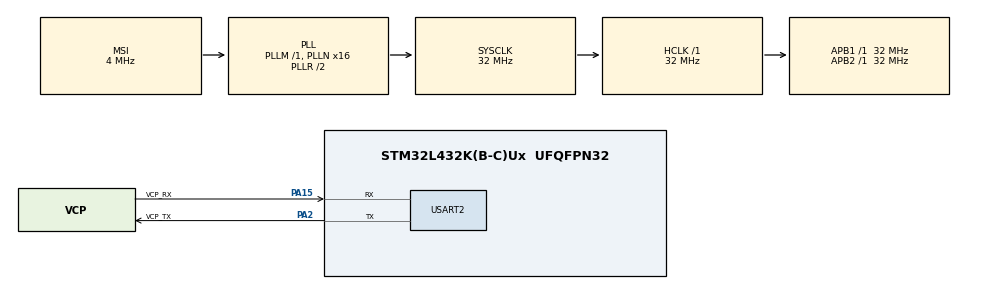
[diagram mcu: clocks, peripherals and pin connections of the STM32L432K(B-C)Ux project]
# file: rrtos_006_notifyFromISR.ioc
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FREERTOS.Tasks01=defaultTask,24,128,StartDefaultTask,Default,NULL,Dynamic,NULL,NULL
FREERTOS.configTOTAL_HEAP_SIZE=4098
FREERTOS.configUSE_NEWLIB_REENTRANT=1
Mcu.Family=STM32L4
Mcu.Name=STM32L432K(B-C)Ux
Mcu.Package=UFQFPN32
NVIC.PriorityGroup=NVIC_PRIORITYGROUP_4
NVIC.TIM1_UP_TIM16_IRQn=true\:6\:0\:true\:false\:true\:true\:true\:true\:true
NVIC.TIM6_DAC_IRQn=true\:15\:0\:false\:false\:true\:false\:false\:true\:true
NVIC.TimeBase=TIM6_DAC_IRQn
NVIC.TimeBaseIP=TIM6
PA0.GPIO_Label=MCO [High speed clock in]
PA0.Mode=HSE-External-Clock-Source-for-LittleOrca
PA0.Signal=RCC_CK_IN
PA13\ (JTMS-SWDIO).GPIO_Label=SWDIO
PA13\ (JTMS-SWDIO).Mode=Serial_Wire
PA13\ (JTMS-SWDIO).Signal=SYS_JTMS-SWDIO
PA14\ (JTCK-SWCLK).GPIO_Label=SWCLK
PA14\ (JTCK-SWCLK).Mode=Serial_Wire
PA14\ (JTCK-SWCLK).Signal=SYS_JTCK-SWCLK
PA15\ (JTDI).GPIO_Label=VCP_RX
PA15\ (JTDI).Mode=Asynchronous
PA15\ (JTDI).Signal=USART2_RX
PA2.GPIO_Label=VCP_TX
PA2.Mode=Asynchronous
PA2.Signal=USART2_TX
PC14-OSC32_IN\ (PC14).Mode=LSE-External-Oscillator
PC14-OSC32_IN\ (PC14).Signal=RCC_OSC32_IN
PC15-OSC32_OUT\ (PC15).Mode=LSE-External-Oscillator
PC15-OSC32_OUT\ (PC15).Signal=RCC_OSC32_OUT
ProjectManager.HeapSize=0x200
ProjectManager.StackSize=0x400
ProjectManager.TargetToolchain=STM32CubeIDE
RCC.AHBFreq_Value=32000000
RCC.APB1Freq_Value=32000000
RCC.APB1TimFreq_Value=32000000
RCC.APB2Freq_Value=32000000
RCC.APB2TimFreq_Value=32000000
RCC.CortexFreq_Value=32000000
RCC.HCLKFreq_Value=32000000
RCC.HSE_VALUE=8000000
RCC.HSI16_VALUE=16000000
RCC.HSI48_VALUE=48000000
RCC.HSI_VALUE=16000000
RCC.MSI_VALUE=4000000
RCC.PLLMUL=RCC_PLLMUL_4
RCC.PLLN=16
RCC.SYSCLKFreq_VALUE=32000000
RCC.SYSCLKSource=RCC_SYSCLKSOURCE_PLLCLK
RCC.VCOOutputFreq_Value=64000000
TIM1.Period=1000-1
TIM1.Prescaler=32000-1
USART2.VirtualMode-Asynchronous=VM_ASYNC
VP_FREERTOS_VS_CMSIS_V2.Mode=CMSIS_V2
VP_SYS_VS_tim6.Mode=TIM6
VP_TIM1_VS_ClockSourceINT.Mode=Internal
board=NUCLEO-L432KC

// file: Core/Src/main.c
/* USER CODE BEGIN Header */
/**
  ******************************************************************************
  * @file           : main.c
  * @brief          : Main program body
  ******************************************************************************
  * @attention
  *
  * Copyright (c) 2025 STMicroelectronics.
  * All rights reserved.
  *
  * This software is licensed under terms that can be found in the LICENSE file
  * in the root directory of this software component.
  * If no LICENSE file comes with this software, it is provided AS-IS.
  *
  ******************************************************************************
  */
/* USER CODE END Header */
#include "main.h"
#include "cmsis_os.h"

/* USER CODE BEGIN Includes */
//NOTE : configLIBRARY_MAX_SYSCALL_INTERRUPT_PRIORITY is 5 , so  for using FromISR() functions , the ISR priority val should be >5
#include"stdint.h"
/* USER CODE END Includes */

TIM_HandleTypeDef htim1;

UART_HandleTypeDef huart2;

/* Definitions for defaultTask */
osThreadId_t defaultTaskHandle;
const osThreadAttr_t defaultTask_attributes = {
  .name = "defaultTask",
  .stack_size = 128 * 4,
  .priority = (osPriority_t) osPriorityNormal,
};
/* USER CODE BEGIN PV */
TaskHandle_t red_handle = NULL;
TaskHandle_t green_handle = NULL;
TaskHandle_t yellow_handle = NULL;
TaskHandle_t button_handle = NULL;
volatile TaskHandle_t* pcurrentHandle = &red_handle;  // initializing with the first task

/*
 *xTaskNotifyFromISR(...)

This sends a notification to a task (pointed to by pcurrentHandle).

It's the ISR-safe version of xTaskNotify().

The last argument &pxHigherPriorityTaskWoken is a pointer to a flag that FreeRTOS sets to pdTRUE if the notified task has higher priority than the task currently running.

portYIELD_FROM_ISR(pxHigherPriorityTaskWoken)

If the notified task is higher priority, this macro tells the scheduler to switch context immediately after the ISR finishes, so that high-priority task can start running right away.

If pxHigherPriorityTaskWoken is pdFALSE, no context switch happens.

🧠 Why this is needed:
In an ISR, FreeRTOS doesn’t switch tasks automatically.

So, if you unblock a higher priority task, and want it to run immediately, you must explicitly request a context switch using portYIELD_FROM_ISR().
 */
 void timerInterruptHandler(void)
 {
	 BaseType_t pxHigherPriorityTaskWoken=pdFAIL;

	 xTaskNotifyFromISR(*(pcurrentHandle),0,eNoAction,&pxHigherPriorityTaskWoken);
	 portYIELD_FROM_ISR(pxHigherPriorityTaskWoken);// requesting context switching manually

 }
/* USER CODE END PV */

void SystemClock_Config(void);
static void MX_GPIO_Init(void);
static void MX_USART2_UART_Init(void);
static void MX_TIM1_Init(void);
void StartDefaultTask(void *argument);

/* USER CODE BEGIN 0 */

/* USER CODE END PFP */

/* Private user code ---------------------------------------------------------*/
/* USER CODE BEGIN 0 */
void red_task(void*);

void green_task(void*);

void yellow_task(void*);
/* USER CODE END 0 */

int main(void)
{

  /* MCU Configuration--------------------------------------------------------*/

  /* Reset of all peripherals, Initializes the Flash interface and the Systick. */
  HAL_Init();

  /* Configure the system clock */
  SystemClock_Config();

  /* Initialize all configured peripherals */
  MX_GPIO_Init();
  MX_USART2_UART_Init();
  MX_TIM1_Init();
  /* USER CODE BEGIN 2 */
  BaseType_t status = 0;

  /* USER CODE END 2 */

  /* Init scheduler */
  osKernelInitialize();

  /* Create the thread(s) */
  /* creation of defaultTask */
  defaultTaskHandle = osThreadNew(StartDefaultTask, NULL, &defaultTask_attributes);

  /* USER CODE BEGIN RTOS_THREADS */
  /* add threads, ... */
  HAL_UART_Transmit(&huart2, (uint8_t*)"Hello\r\n", sizeof("Hello\r\n") - 1, 1000);

//  printHeapSize();
  status = xTaskCreate(red_task, "Led1", 100, NULL, 1, &red_handle);
  if (status != pdPASS) HAL_UART_Transmit(&huart2, (uint8_t*)"Task1 creation failed\r\n", sizeof("Task1 creation failed\r\n") - 1, 1000);
  configASSERT(status == pdPASS);

//  printHeapSize();

  status = xTaskCreate(green_task, "Led2", 100, NULL, 3, &green_handle);
  if (status != pdPASS) HAL_UART_Transmit(&huart2, (uint8_t*)"Task2 creation failed\r\n", sizeof("Task2 creation failed\r\n") - 1, 1000);
  configASSERT(status == pdPASS);

//  printHeapSize();

  status = xTaskCreate(yellow_task, "Led3", 100, NULL, 2, &yellow_handle);
  if (status != pdPASS) HAL_UART_Transmit(&huart2, (uint8_t*)"Task3 creation failed\r\n", sizeof("Task3 creation failed\r\n") - 1, 1000);
  configASSERT(status == pdPASS);
  HAL_UART_Transmit(&huart2, (uint8_t*)"All task created successfully\r\n", sizeof("All task created successfully\r\n") - 1, 1000);

  HAL_TIM_Base_Start_IT(&htim1);
   vTaskStartScheduler();
   HAL_UART_Transmit(&huart2, (uint8_t*)"Scheduler initialization failed\r\n", sizeof("Scheduler initialization failed\r\n") - 1, 1000);

  /* USER CODE END RTOS_THREADS */

  /* Start scheduler */
  osKernelStart();
  /* We should never get here as control is now taken by the scheduler */
  /* Infinite loop */
  while (1)
  {

  }
}

void SystemClock_Config(void)
{
  RCC_OscInitTypeDef RCC_OscInitStruct = {0};
  RCC_ClkInitTypeDef RCC_ClkInitStruct = {0};

  /** Configure the main internal regulator output voltage
  */
  if (HAL_PWREx_ControlVoltageScaling(PWR_REGULATOR_VOLTAGE_SCALE1) != HAL_OK)
  {
    Error_Handler();
  }

  /** Configure LSE Drive Capability
  */
  HAL_PWR_EnableBkUpAccess();
  __HAL_RCC_LSEDRIVE_CONFIG(RCC_LSEDRIVE_LOW);

  /** Initializes the RCC Oscillators according to the specified parameters
  * in the RCC_OscInitTypeDef structure.
  */
  RCC_OscInitStruct.OscillatorType = RCC_OSCILLATORTYPE_LSE|RCC_OSCILLATORTYPE_MSI;
  RCC_OscInitStruct.LSEState = RCC_LSE_ON;
  RCC_OscInitStruct.MSIState = RCC_MSI_ON;
  RCC_OscInitStruct.MSICalibrationValue = 0;
  RCC_OscInitStruct.MSIClockRange = RCC_MSIRANGE_6;
  RCC_OscInitStruct.PLL.PLLState = RCC_PLL_ON;
  RCC_OscInitStruct.PLL.PLLSource = RCC_PLLSOURCE_MSI;
  RCC_OscInitStruct.PLL.PLLM = 1;
  RCC_OscInitStruct.PLL.PLLN = 16;
  RCC_OscInitStruct.PLL.PLLP = RCC_PLLP_DIV7;
  RCC_OscInitStruct.PLL.PLLQ = RCC_PLLQ_DIV2;
  RCC_OscInitStruct.PLL.PLLR = RCC_PLLR_DIV2;
  if (HAL_RCC_OscConfig(&RCC_OscInitStruct) != HAL_OK)
  {
    Error_Handler();
  }

  /** Initializes the CPU, AHB and APB buses clocks
  */
  RCC_ClkInitStruct.ClockType = RCC_CLOCKTYPE_HCLK|RCC_CLOCKTYPE_SYSCLK
                              |RCC_CLOCKTYPE_PCLK1|RCC_CLOCKTYPE_PCLK2;
  RCC_ClkInitStruct.SYSCLKSource = RCC_SYSCLKSOURCE_PLLCLK;
  RCC_ClkInitStruct.AHBCLKDivider = RCC_SYSCLK_DIV1;
  RCC_ClkInitStruct.APB1CLKDivider = RCC_HCLK_DIV1;
  RCC_ClkInitStruct.APB2CLKDivider = RCC_HCLK_DIV1;

  if (HAL_RCC_ClockConfig(&RCC_ClkInitStruct, FLASH_LATENCY_1) != HAL_OK)
  {
    Error_Handler();
  }

  /** Enable MSI Auto calibration
  */
  HAL_RCCEx_EnableMSIPLLMode();
}

static void MX_TIM1_Init(void)
{

  TIM_ClockConfigTypeDef sClockSourceConfig = {0};
  TIM_MasterConfigTypeDef sMasterConfig = {0};

  htim1.Instance = TIM1;
  htim1.Init.Prescaler = 32000-1;
  htim1.Init.CounterMode = TIM_COUNTERMODE_UP;
  htim1.Init.Period = 1000-1;
  htim1.Init.ClockDivision = TIM_CLOCKDIVISION_DIV1;
  htim1.Init.RepetitionCounter = 0;
  htim1.Init.AutoReloadPreload = TIM_AUTORELOAD_PRELOAD_DISABLE;
  if (HAL_TIM_Base_Init(&htim1) != HAL_OK)
  {
    Error_Handler();
  }
  sClockSourceConfig.ClockSource = TIM_CLOCKSOURCE_INTERNAL;
  if (HAL_TIM_ConfigClockSource(&htim1, &sClockSourceConfig) != HAL_OK)
  {
    Error_Handler();
  }
  sMasterConfig.MasterOutputTrigger = TIM_TRGO_RESET;
  sMasterConfig.MasterOutputTrigger2 = TIM_TRGO2_RESET;
  sMasterConfig.MasterSlaveMode = TIM_MASTERSLAVEMODE_DISABLE;
  if (HAL_TIMEx_MasterConfigSynchronization(&htim1, &sMasterConfig) != HAL_OK)
  {
    Error_Handler();
  }

}

static void MX_USART2_UART_Init(void)
{

  huart2.Instance = USART2;
  huart2.Init.BaudRate = 115200;
  huart2.Init.WordLength = UART_WORDLENGTH_8B;
  huart2.Init.StopBits = UART_STOPBITS_1;
  huart2.Init.Parity = UART_PARITY_NONE;
  huart2.Init.Mode = UART_MODE_TX_RX;
  huart2.Init.HwFlowCtl = UART_HWCONTROL_NONE;
  huart2.Init.OverSampling = UART_OVERSAMPLING_16;
  huart2.Init.OneBitSampling = UART_ONE_BIT_SAMPLE_DISABLE;
  huart2.AdvancedInit.AdvFeatureInit = UART_ADVFEATURE_NO_INIT;
  if (HAL_UART_Init(&huart2) != HAL_OK)
  {
    Error_Handler();
  }

}

static void MX_GPIO_Init(void)
{

  /* GPIO Ports Clock Enable */
  __HAL_RCC_GPIOC_CLK_ENABLE();
  __HAL_RCC_GPIOA_CLK_ENABLE();

}

/* USER CODE BEGIN 4 */
void red_task(void* para) {
  while (1) {

    if (xTaskNotifyWait(0, 0, NULL, pdMS_TO_TICKS(1000)) == pdPASS) {
      portENTER_CRITICAL();
      HAL_UART_Transmit(&huart2, (uint8_t*)"Red task Running \r\n", sizeof("Red task Running \r\n") - 1, 1000);
      pcurrentHandle = &green_handle;
      portEXIT_CRITICAL();
    }
  }
}
void green_task(void* para) {
  while (1) {
    if (xTaskNotifyWait(0, 0, NULL, pdMS_TO_TICKS(1000)) == pdPASS) {
  	  portENTER_CRITICAL();
      HAL_UART_Transmit(&huart2, (uint8_t*)"Green task Running \r\n", sizeof("Green task Running \r\n") - 1, 1000);
      pcurrentHandle = &yellow_handle;
      portEXIT_CRITICAL();
    }
  }
}
void yellow_task(void* para) {
  while (1) {
    if (xTaskNotifyWait(0, 0, NULL, pdMS_TO_TICKS(1000)) == pdPASS) {
       portENTER_CRITICAL();
       HAL_UART_Transmit(&huart2, (uint8_t*)"Yellow task Running \r\n", sizeof("Yellow task Running \r\n") - 1, 1000);
       pcurrentHandle = &red_handle;
       portEXIT_CRITICAL();
    }
  }
}
/* USER CODE END 4 */

void StartDefaultTask(void *argument)
{
  for(;;)
  {
    osDelay(1);
  }
}

void HAL_TIM_PeriodElapsedCallback(TIM_HandleTypeDef *htim)
{
  if (htim->Instance == TIM6) {
    HAL_IncTick();
  }
}

void Error_Handler(void)
{
  __disable_irq();
  while (1)
  {
  }
}
